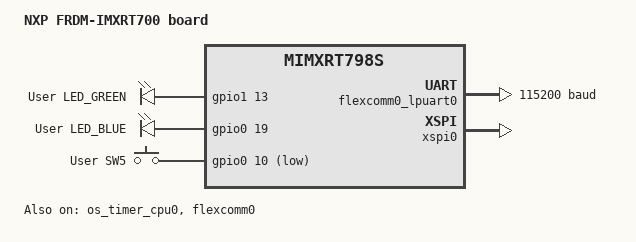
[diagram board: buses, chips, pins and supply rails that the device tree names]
/*
 * Copyright 2026 NXP
 *
 * SPDX-License-Identifier: Apache-2.0
 */

/dts-v1/;

#include <nxp/imxrt/nxp_rt7xx_cm33_cpu0.dtsi>
#include <zephyr/dt-bindings/input/input-event-codes.h>
#include "frdm_imxrt700-pinctrl.dtsi"

/ {
	model = "NXP FRDM-IMXRT700 board";
	compatible = "nxp,mimxrt798s";

	aliases {
		led0 = &green_led;
		led1 = &blue_led;
		sw0 = &user_button_1;
	};

	chosen {
		zephyr,flash = &ext_flash;
		zephyr,sram = &sram0;
		zephyr,console = &flexcomm0_lpuart0;
		zephyr,shell-uart = &flexcomm0_lpuart0;
	};

	leds {
		compatible = "gpio-leds";

		green_led: led_0 {
			gpios = <&gpio1 13 GPIO_ACTIVE_HIGH>;
			label = "User LED_GREEN";
		};

		blue_led: led_1 {
			gpios = <&gpio0 19 GPIO_ACTIVE_HIGH>;
			label = "User LED_BLUE";
		};
	};

	gpio_keys {
		compatible = "gpio-keys";

		user_button_1: button_0 {
			label = "User SW5";
			gpios = <&gpio0 10 GPIO_ACTIVE_LOW>;
			zephyr,code = <INPUT_KEY_0>;
		};
	};

	/*
	 * FRDM-IMXRT700 populates a Winbond W25Q25PW quad SPI NOR
	 * (32MB / 256Mbit) on XSPI0, unlike the MIMXRT700-EVK octal
	 * MX25UM51345G. The boot ROM configures XSPI0 for XIP from the
	 * boot configuration block (flash_config/flash_config.c), so code
	 * executes in place from the memory-mapped window at 0x38000000.
	 *
	 * The Zephyr nxp,xspi-nor flash driver does not support the
	 * W25Q25PW quad part yet, so the flash is described as a bare
	 * memory-mapped region without a flash controller and is left
	 * unpartitioned. Rework this into a flash controller child node
	 * with partitions once the driver gains support for this part
	 * and runtime flash access (storage/NVS/MCUboot) is needed.
	 */
	ext_flash: flash@38000000 {
		compatible = "soc-nv-flash";
		reg = <0x38000000 DT_SIZE_M(32)>;
		erase-block-size = <DT_SIZE_K(4)>;
		write-block-size = <4>;
	};
};

/*
 * RT700-FRDM board cm33_cpu0 uses OS timer as the kernel timer
 * In case we need to switch to SYSTICK timer, then
 * replace &os_timer with &systick
 */
&os_timer_cpu0 {
	status = "okay";
	wakeup-source;
};

&flexcomm0 {
	status = "okay";
};

&flexcomm0_lpuart0 {
	status = "okay";
	current-speed = <115200>;
	pinctrl-0 = <&pinmux_flexcomm0_lpuart>;
	pinctrl-names = "default";
};

&gpio0 {
	status = "okay";
};

&gpio1 {
	status = "okay";
};

&green_led {
	status = "okay";
};

&blue_led {
	status = "okay";
};

/*
 * XSPI0 hosts the XIP boot flash (see the ext_flash node). No pinctrl or
 * flash controller child is attached: the boot ROM has already configured
 * the pins and the controller for XIP. The node must stay enabled, though:
 * the boot header machinery (BOOT_XSPI_NOR and the flash config block
 * placement) depends on an enabled nxp,xspi node, and
 * board_early_init_hook() keys the XSPI0 power domain keep-alive on it.
 */
&xspi0 {
	status = "okay";
};
